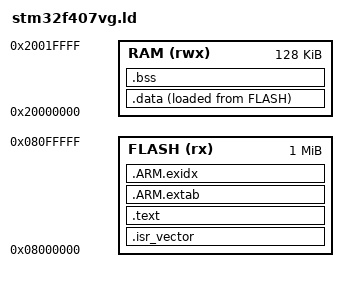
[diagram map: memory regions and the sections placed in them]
ENTRY(Reset_Handler)

_estack = ORIGIN(RAM) + LENGTH(RAM);

MEMORY
{
    FLASH (rx)  : ORIGIN = 0x08000000, LENGTH = 1024K
    RAM   (rwx) : ORIGIN = 0x20000000, LENGTH = 128K
}

SECTIONS
{
    .isr_vector ORIGIN(FLASH) : ALIGN(512)
    {
        KEEP(*(.isr_vector))
    } > FLASH

    .text :
    {
        . = ALIGN(4);
        *(.text*)
        *(.rodata*)
        *(.glue_7)
        *(.glue_7t)
        KEEP(*(.init))
        KEEP(*(.fini))
        . = ALIGN(4);
    } > FLASH

    .ARM.extab :
    {
        *(.ARM.extab* .gnu.linkonce.armextab.*)
    } > FLASH

    .ARM.exidx :
    {
        __exidx_start = .;
        *(.ARM.exidx*)
        __exidx_end = .;
    } > FLASH

    _sidata = LOADADDR(.data);
    .data :
    {
        . = ALIGN(4);
        _sdata = .;
        *(.data*)
        . = ALIGN(4);
        _edata = .;
    } > RAM AT > FLASH

    .bss (NOLOAD) :
    {
        . = ALIGN(4);
        _sbss = .;
        *(.bss*)
        *(COMMON)
        . = ALIGN(4);
        _ebss = .;
    } > RAM

    /DISCARD/ :
    {
        *(.comment*)
        *(.note*)
    }
}

ASSERT(_ebss <= _estack - 1024, "RAM overflow: reserve at least 1 KiB for stack")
